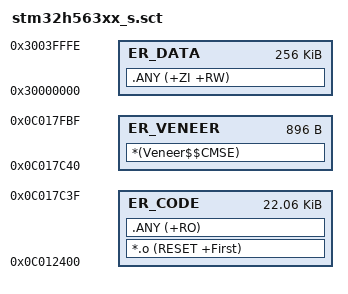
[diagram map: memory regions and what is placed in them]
#! armclang --target=arm-arm-none-eabi -march=armv8-m.main -E -xc

/*
 * Copyright (c) 2017-2018 ARM Limited
 *
 * Licensed under the Apache License, Version 2.0 (the "License");
 * you may not use this file except in compliance with the License.
 * You may obtain a copy of the License at
 *
 *     http://www.apache.org/licenses/LICENSE-2.0
 *
 * Unless required by applicable law or agreed to in writing, software
 * distributed under the License is distributed on an "AS IS" BASIS,
 * WITHOUT WARRANTIES OR CONDITIONS OF ANY KIND, either express or implied.
 * See the License for the specific language governing permissions and
 * limitations under the License.
 */

#define S_CODE_OFFSET 0x12000                       /* This define is updated automatically from ROT_BOOT project */
#define S_CODE_SIZE 0x6000                          /* This define is updated automatically from ROT_BOOT project */
#define NS_CODE_OFFSET S_CODE_OFFSET + S_CODE_SIZE  /* Non secure code Offset */
#define IMAGE_HEADER_SIZE 0x400                     /* mcuboot headre size */
#define TRAILER_MAX_SIZE 0x40                       /* max size trailer */

#define S_CODE_START 0x0C000000 + S_CODE_OFFSET + IMAGE_HEADER_SIZE
#define S_APP_CODE_SIZE S_CODE_SIZE - CMSE_VENEER_REGION_SIZE - TRAILER_MAX_SIZE - IMAGE_HEADER_SIZE

#define NS_CODE_START 0x08100000
#define NS_CODE_SIZE 0xFFFFF

#define S_DATA_START 0x30000000
#define S_DATA_SIZE 0x3FFFF

#define S_CODE_LIMIT (S_CODE_START + S_APP_CODE_SIZE - 1)

#define CMSE_VENEER_REGION_START S_CODE_LIMIT + 1
#define CMSE_VENEER_REGION_SIZE 0x00000380

LR_CODE S_CODE_START {
    ER_CODE S_CODE_START S_APP_CODE_SIZE {
        *.o (RESET +First)
        .ANY (+RO)
    }

    ER_DATA S_DATA_START S_DATA_SIZE {
        .ANY (+ZI +RW)
    }
}

LR_VENEER CMSE_VENEER_REGION_START CMSE_VENEER_REGION_SIZE  {
  ER_VENEER CMSE_VENEER_REGION_START CMSE_VENEER_REGION_SIZE  {
   *(Veneer$$CMSE)
  }
}
